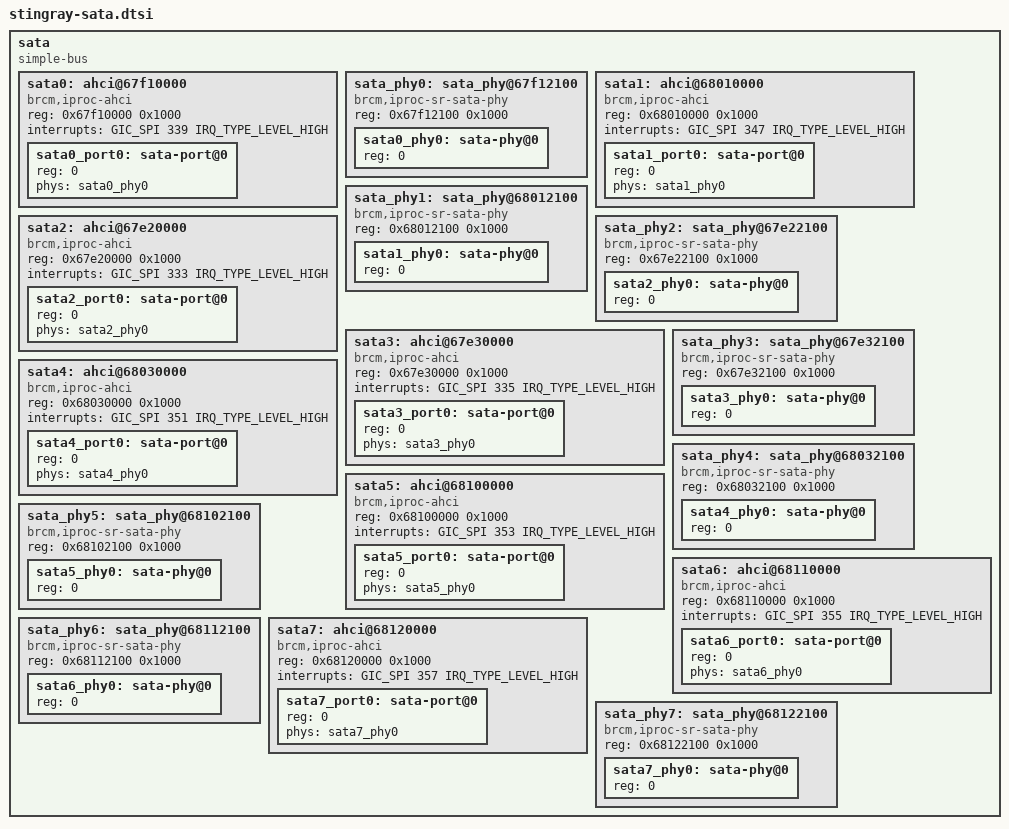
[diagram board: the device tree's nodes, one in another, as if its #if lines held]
/*
 *  BSD LICENSE
 *
 *  Copyright(c) 2016-2017 Broadcom.  All rights reserved.
 *
 *  Redistribution and use in source and binary forms, with or without
 *  modification, are permitted provided that the following conditions
 *  are met:
 *
 *    * Redistributions of source code must retain the above copyright
 *      notice, this list of conditions and the following disclaimer.
 *    * Redistributions in binary form must reproduce the above copyright
 *      notice, this list of conditions and the following disclaimer in
 *      the documentation and/or other materials provided with the
 *      distribution.
 *    * Neither the name of Broadcom nor the names of its
 *      contributors may be used to endorse or promote products derived
 *      from this software without specific prior written permission.
 *
 *  THIS SOFTWARE IS PROVIDED BY THE COPYRIGHT HOLDERS AND CONTRIBUTORS
 *  "AS IS" AND ANY EXPRESS OR IMPLIED WARRANTIES, INCLUDING, BUT NOT
 *  LIMITED TO, THE IMPLIED WARRANTIES OF MERCHANTABILITY AND FITNESS FOR
 *  A PARTICULAR PURPOSE ARE DISCLAIMED. IN NO EVENT SHALL THE COPYRIGHT
 *  OWNER OR CONTRIBUTORS BE LIABLE FOR ANY DIRECT, INDIRECT, INCIDENTAL,
 *  SPECIAL, EXEMPLARY, OR CONSEQUENTIAL DAMAGES (INCLUDING, BUT NOT
 *  LIMITED TO, PROCUREMENT OF SUBSTITUTE GOODS OR SERVICES; LOSS OF USE,
 *  DATA, OR PROFITS; OR BUSINESS INTERRUPTION) HOWEVER CAUSED AND ON ANY
 *  THEORY OF LIABILITY, WHETHER IN CONTRACT, STRICT LIABILITY, OR TORT
 *  (INCLUDING NEGLIGENCE OR OTHERWISE) ARISING IN ANY WAY OUT OF THE USE
 *  OF THIS SOFTWARE, EVEN IF ADVISED OF THE POSSIBILITY OF SUCH DAMAGE.
 */

	sata {
		compatible = "simple-bus";
		#address-cells = <1>;
		#size-cells = <1>;
		ranges = <0 0 0 0xffffffff>;

		sata0: ahci@67f10000 {
			compatible = "brcm,iproc-ahci", "generic-ahci";
			reg = <0x67f10000 0x1000>;
			reg-names = "ahci";
			interrupts = <GIC_SPI 339 IRQ_TYPE_LEVEL_HIGH>;
			#address-cells = <1>;
			#size-cells = <0>;
#if (NUM_SATA > 0)
			status = "okay";
#else
			status = "disabled";
#endif

			sata0_port0: sata-port@0 {
				reg = <0>;
				phys = <&sata0_phy0>;
				phy-names = "sata-phy";
			};
		};

		sata_phy0: sata_phy@67f12100 {
			compatible = "brcm,iproc-sr-sata-phy";
			reg = <0x67f12100 0x1000>;
			reg-names = "phy";
			#address-cells = <1>;
			#size-cells = <0>;
#if (NUM_SATA > 0)
			status = "okay";
#else
			status = "disabled";
#endif

			sata0_phy0: sata-phy@0 {
				reg = <0>;
				#phy-cells = <0>;
			};
		};

		sata1: ahci@68010000 {
			compatible = "brcm,iproc-ahci", "generic-ahci";
			reg = <0x68010000 0x1000>;
			reg-names = "ahci";
			interrupts = <GIC_SPI 347 IRQ_TYPE_LEVEL_HIGH>;
			#address-cells = <1>;
			#size-cells = <0>;
#if (NUM_SATA > 1)
			status = "okay";
#else
			status = "disabled";
#endif

			sata1_port0: sata-port@0 {
				reg = <0>;
				phys = <&sata1_phy0>;
				phy-names = "sata-phy";
			};
		};

		sata_phy1: sata_phy@68012100 {
			compatible = "brcm,iproc-sr-sata-phy";
			reg = <0x68012100 0x1000>;
			reg-names = "phy";
			#address-cells = <1>;
			#size-cells = <0>;
#if (NUM_SATA > 1)
			status = "okay";
#else
			status = "disabled";
#endif

			sata1_phy0: sata-phy@0 {
				reg = <0>;
				#phy-cells = <0>;
			};
		};

		sata2: ahci@67e20000 {
			compatible = "brcm,iproc-ahci", "generic-ahci";
			reg = <0x67e20000 0x1000>;
			reg-names = "ahci";
			interrupts = <GIC_SPI 333 IRQ_TYPE_LEVEL_HIGH>;
			#address-cells = <1>;
			#size-cells = <0>;
#if (NUM_SATA > 2)
			status = "okay";
#else
			status = "disabled";
#endif

			sata2_port0: sata-port@0 {
				reg = <0>;
				phys = <&sata2_phy0>;
				phy-names = "sata-phy";
			};
		};

		sata_phy2: sata_phy@67e22100 {
			compatible = "brcm,iproc-sr-sata-phy";
			reg = <0x67e22100 0x1000>;
			reg-names = "phy";
			#address-cells = <1>;
			#size-cells = <0>;
#if (NUM_SATA > 2)
			status = "okay";
#else
			status = "disabled";
#endif

			sata2_phy0: sata-phy@0 {
				reg = <0>;
				#phy-cells = <0>;
			};
		};

		sata3: ahci@67e30000 {
			compatible = "brcm,iproc-ahci", "generic-ahci";
			reg = <0x67e30000 0x1000>;
			reg-names = "ahci";
			interrupts = <GIC_SPI 335 IRQ_TYPE_LEVEL_HIGH>;
			#address-cells = <1>;
			#size-cells = <0>;
#if (NUM_SATA > 3)
			status = "okay";
#else
			status = "disabled";
#endif

			sata3_port0: sata-port@0 {
				reg = <0>;
				phys = <&sata3_phy0>;
				phy-names = "sata-phy";
			};
		};

		sata_phy3: sata_phy@67e32100 {
			compatible = "brcm,iproc-sr-sata-phy";
			reg = <0x67e32100 0x1000>;
			reg-names = "phy";
			#address-cells = <1>;
			#size-cells = <0>;
#if (NUM_SATA > 3)
			status = "okay";
#else
			status = "disabled";
#endif

			sata3_phy0: sata-phy@0 {
				reg = <0>;
				#phy-cells = <0>;
			};
		};

		sata4: ahci@68030000 {
			compatible = "brcm,iproc-ahci", "generic-ahci";
			reg = <0x68030000 0x1000>;
			reg-names = "ahci";
			interrupts = <GIC_SPI 351 IRQ_TYPE_LEVEL_HIGH>;
			#address-cells = <1>;
			#size-cells = <0>;
#if (NUM_SATA > 4)
			status = "okay";
#else
			status = "disabled";
#endif

			sata4_port0: sata-port@0 {
				reg = <0>;
				phys = <&sata4_phy0>;
				phy-names = "sata-phy";
			};
		};

		sata_phy4: sata_phy@68032100 {
			compatible = "brcm,iproc-sr-sata-phy";
			reg = <0x68032100 0x1000>;
			reg-names = "phy";
			#address-cells = <1>;
			#size-cells = <0>;
#if (NUM_SATA > 4)
			status = "okay";
#else
			status = "disabled";
#endif

			sata4_phy0: sata-phy@0 {
				reg = <0>;
				#phy-cells = <0>;
			};
		};

		sata5: ahci@68100000 {
			compatible = "brcm,iproc-ahci", "generic-ahci";
			reg = <0x68100000 0x1000>;
			reg-names = "ahci";
			interrupts = <GIC_SPI 353 IRQ_TYPE_LEVEL_HIGH>;
			#address-cells = <1>;
			#size-cells = <0>;
#if (NUM_SATA > 5)
			status = "okay";
#else
			status = "disabled";
#endif

			sata5_port0: sata-port@0 {
				reg = <0>;
				phys = <&sata5_phy0>;
				phy-names = "sata-phy";
			};
		};

		sata_phy5: sata_phy@68102100 {
			compatible = "brcm,iproc-sr-sata-phy";
			reg = <0x68102100 0x1000>;
			reg-names = "phy";
			#address-cells = <1>;
			#size-cells = <0>;
#if (NUM_SATA > 5)
			status = "okay";
#else
			status = "disabled";
#endif

			sata5_phy0: sata-phy@0 {
				reg = <0>;
				#phy-cells = <0>;
			};
		};

		sata6: ahci@68110000 {
			compatible = "brcm,iproc-ahci", "generic-ahci";
			reg = <0x68110000 0x1000>;
			reg-names = "ahci";
			interrupts = <GIC_SPI 355 IRQ_TYPE_LEVEL_HIGH>;
			#address-cells = <1>;
			#size-cells = <0>;
#if (NUM_SATA > 6)
			status = "okay";
#else
			status = "disabled";
#endif

			sata6_port0: sata-port@0 {
				reg = <0>;
				phys = <&sata6_phy0>;
				phy-names = "sata-phy";
			};
		};

		sata_phy6: sata_phy@68112100 {
			compatible = "brcm,iproc-sr-sata-phy";
			reg = <0x68112100 0x1000>;
			reg-names = "phy";
			#address-cells = <1>;
			#size-cells = <0>;
#if (NUM_SATA > 6)
			status = "okay";
#else
			status = "disabled";
#endif

			sata6_phy0: sata-phy@0 {
				reg = <0>;
				#phy-cells = <0>;
			};
		};

		sata7: ahci@68120000 {
			compatible = "brcm,iproc-ahci", "generic-ahci";
			reg = <0x68120000 0x1000>;
			reg-names = "ahci";
			interrupts = <GIC_SPI 357 IRQ_TYPE_LEVEL_HIGH>;
			#address-cells = <1>;
			#size-cells = <0>;
#if (NUM_SATA > 7)
			status = "okay";
#else
			status = "disabled";
#endif

			sata7_port0: sata-port@0 {
				reg = <0>;
				phys = <&sata7_phy0>;
				phy-names = "sata-phy";
			};
		};

		sata_phy7: sata_phy@68122100 {
			compatible = "brcm,iproc-sr-sata-phy";
			reg = <0x68122100 0x1000>;
			reg-names = "phy";
			#address-cells = <1>;
			#size-cells = <0>;
#if (NUM_SATA > 7)
			status = "okay";
#else
			status = "disabled";
#endif

			sata7_phy0: sata-phy@0 {
				reg = <0>;
				#phy-cells = <0>;
			};
		};

#if (NUM_SATA > 8)
#error "NUM_SATA > 8"
#endif
	};

